# MC1322x register map
Registers from a debugger description file.
Registers are 32-bit, access not given, no defined reset value unless marked. A register's access mark holds for its fields unless they carry their own. Addresses are absolute; registers are grouped by the start of their names; lines under a group give offsets from that group; [hi:lo] are bit positions; {n}, {i} and the like mark numbered series; 'fields as' and 'values as' point back to an identical list; <NAME> marks a mode.

## PAD
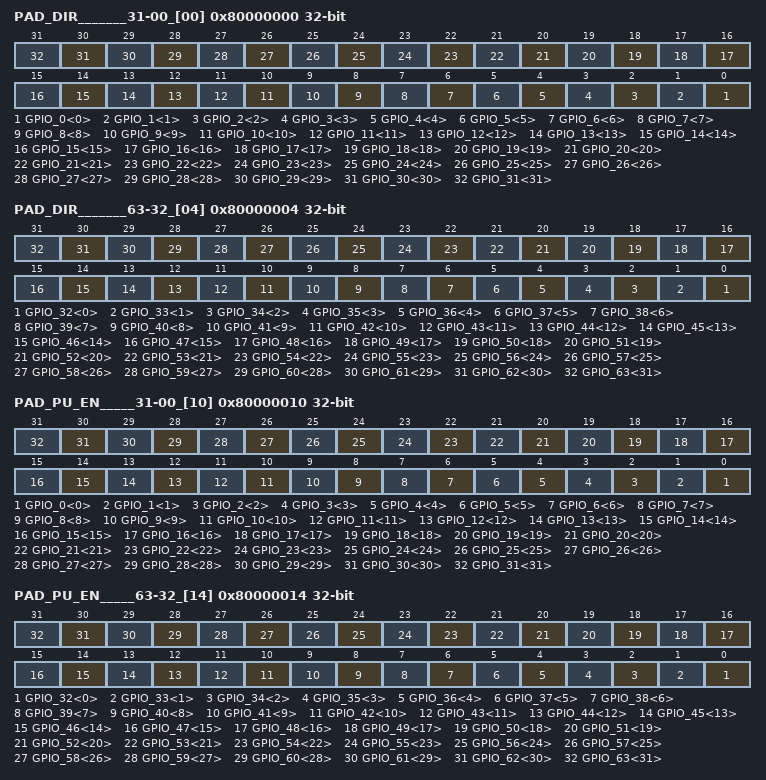
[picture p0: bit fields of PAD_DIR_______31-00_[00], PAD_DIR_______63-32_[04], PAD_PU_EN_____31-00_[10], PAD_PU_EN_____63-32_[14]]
0x80000000 PAD_DIR_______31-00_[00]
  [n] GPIO_{n}<{n}> (n=0..31)
0x80000004 PAD_DIR_______63-32_[04]
  [n-32] GPIO_{n}<{n-32}> (n=32..63)
0x80000010 PAD_PU_EN_____31-00_[10]
  [n] GPIO_{n}<{n}> (n=0..31)
0x80000014 PAD_PU_EN_____63-32_[14]
  [n-32] GPIO_{n}<{n-32}> (n=32..63)
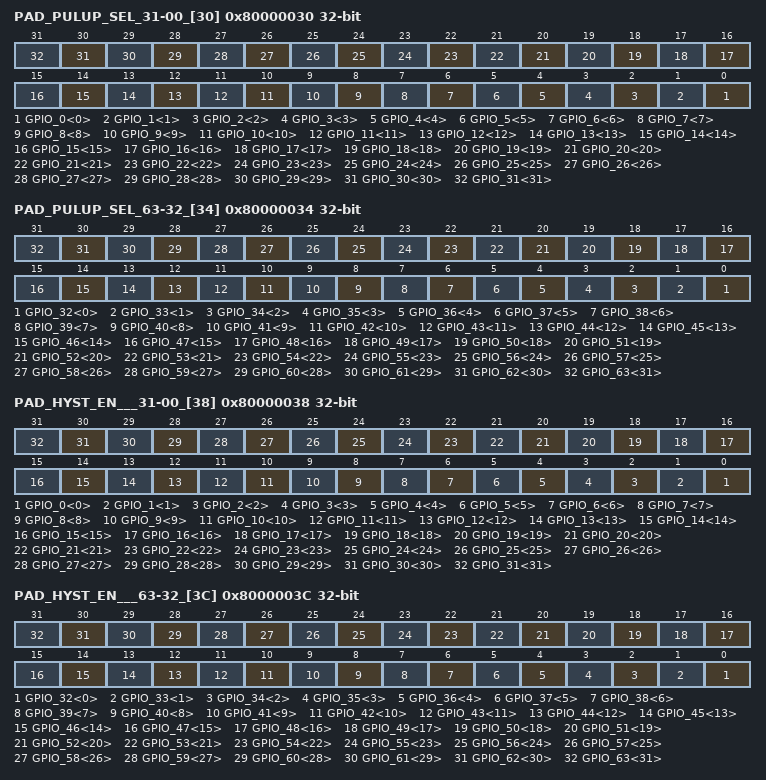
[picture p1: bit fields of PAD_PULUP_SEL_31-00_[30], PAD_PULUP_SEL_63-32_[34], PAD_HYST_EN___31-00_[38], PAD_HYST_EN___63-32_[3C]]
0x80000030 PAD_PULUP_SEL_31-00_[30]
  [n] GPIO_{n}<{n}> (n=0..31)
0x80000034 PAD_PULUP_SEL_63-32_[34]
  [n-32] GPIO_{n}<{n-32}> (n=32..63)
0x80000038 PAD_HYST_EN___31-00_[38]
  [n] GPIO_{n}<{n}> (n=0..31)
0x8000003C PAD_HYST_EN___63-32_[3C]
  [n-32] GPIO_{n}<{n-32}> (n=32..63)

## SFR
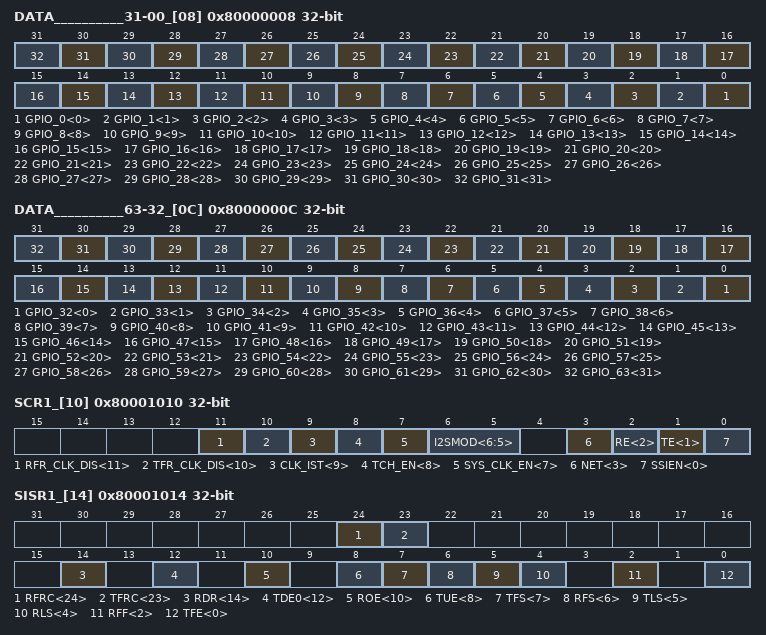
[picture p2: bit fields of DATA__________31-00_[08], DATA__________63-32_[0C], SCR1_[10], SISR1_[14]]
0x80000008 DATA__________31-00_[08]
  [n] GPIO_{n}<{n}> (n=0..31)
0x8000000C DATA__________63-32_[0C]
  [n-32] GPIO_{n}<{n-32}> (n=32..63)
0x80001000 STX_[00]
0x80001008 SRX_[08]
0x80001010 SCR1_[10]
  [11] RFR_CLK_DIS<11>, [10] TFR_CLK_DIS<10>, [9] CLK_IST<9>, [8] TCH_EN<8>, [7] SYS_CLK_EN<7>, [6:5] I2SMOD<6:5>, [3] NET<3>, [2] RE<2>, [1] TE<1>, [0] SSIEN<0>
0x80001014 SISR1_[14]
  [24] RFRC<24>, [23] TFRC<23>, [14] RDR<14>, [12] TDE0<12>, [10] ROE<10>, [8] TUE<8>, [7] TFS<7>, [6] RFS<6>, [5] TLS<5>, [4] RLS<4>, [2] RFF<2>, [0] TFE<0>
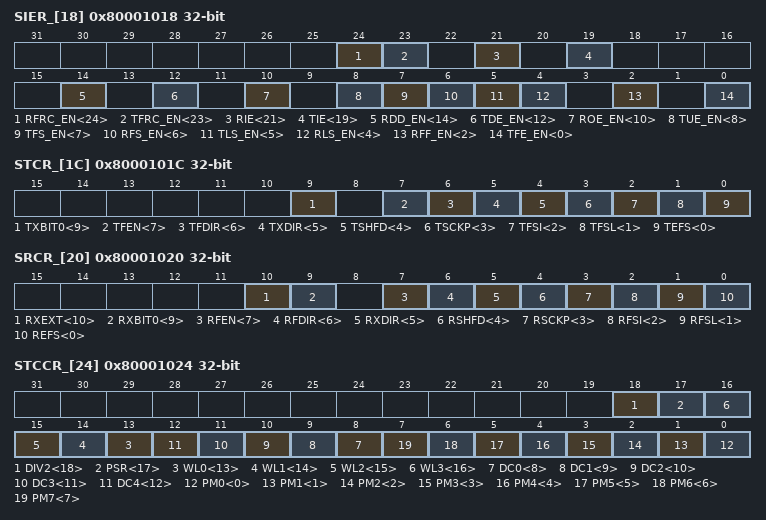
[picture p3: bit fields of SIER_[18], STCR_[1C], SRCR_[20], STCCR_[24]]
0x80001018 SIER_[18]
  [24] RFRC_EN<24>, [23] TFRC_EN<23>, [21] RIE<21>, [19] TIE<19>, [14] RDD_EN<14>, [12] TDE_EN<12>, [10] ROE_EN<10>, [8] TUE_EN<8>, [7] TFS_EN<7>, [6] RFS_EN<6>, [5] TLS_EN<5>, [4] RLS_EN<4>, [2] RFF_EN<2>, [0] TFE_EN<0>
0x8000101C STCR_[1C]
  [9] TXBIT0<9>, [7] TFEN<7>, [6] TFDIR<6>, [5] TXDIR<5>, [4] TSHFD<4>, [3] TSCKP<3>, [2] TFSI<2>, [1] TFSL<1>, [0] TEFS<0>
0x80001020 SRCR_[20]
  [10] RXEXT<10>, [9] RXBIT0<9>, [7] RFEN<7>, [6] RFDIR<6>, [5] RXDIR<5>, [4] RSHFD<4>, [3] RSCKP<3>, [2] RFSI<2>, [1] RFSL<1>, [0] REFS<0>
0x80001024 STCCR_[24]
  [18] DIV2<18>, [17] PSR<17>, [n+13] WL{n}<{n+13}> (n=0..3), [n+8] DC{n}<{n+8}> (n=0..4), [n] PM{n}<{n}> (n=0..7)
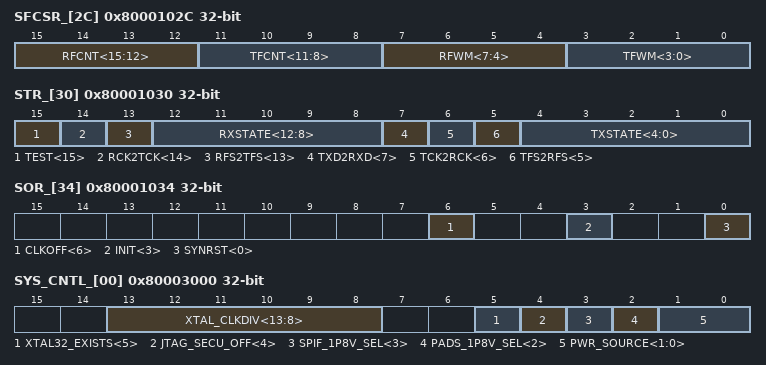
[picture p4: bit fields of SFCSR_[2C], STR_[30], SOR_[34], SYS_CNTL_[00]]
0x8000102C SFCSR_[2C]
  [15:12] RFCNT<15:12>, [11:8] TFCNT<11:8>, [7:4] RFWM<7:4>, [3:0] TFWM<3:0>
0x80001030 STR_[30]
  [15] TEST<15>, [14] RCK2TCK<14>, [13] RFS2TFS<13>, [12:8] RXSTATE<12:8>, [7] TXD2RXD<7>, [6] TCK2RCK<6>, [5] TFS2RFS<5>, [4:0] TXSTATE<4:0>
0x80001034 SOR_[34]
  [6] CLKOFF<6>, [3] INIT<3>, [0] SYNRST<0>
0x80001048 STMSK_[48]
0x8000104C SRMSK_[4C]
0x80003000 SYS_CNTL_[00]
  [13:8] XTAL_CLKDIV<13:8>, [5] XTAL32_EXISTS<5>, [4] JTAG_SECU_OFF<4>, [3] SPIF_1P8V_SEL<3>, [2] PADS_1P8V_SEL<2>, [1:0] PWR_SOURCE<1:0>
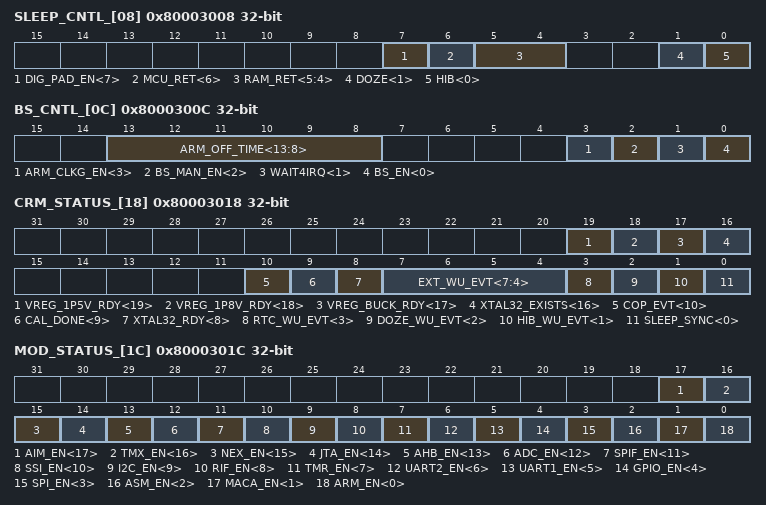
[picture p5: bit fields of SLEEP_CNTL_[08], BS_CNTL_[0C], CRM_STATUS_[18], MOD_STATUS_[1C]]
0x80003008 SLEEP_CNTL_[08]
  [7] DIG_PAD_EN<7>, [6] MCU_RET<6>, [5:4] RAM_RET<5:4>, [1] DOZE<1>, [0] HIB<0>
0x8000300C BS_CNTL_[0C]
  [13:8] ARM_OFF_TIME<13:8>, [3] ARM_CLKG_EN<3>, [2] BS_MAN_EN<2>, [1] WAIT4IRQ<1>, [0] BS_EN<0>
0x80003018 CRM_STATUS_[18]
  [19] VREG_1P5V_RDY<19>, [18] VREG_1P8V_RDY<18>, [17] VREG_BUCK_RDY<17>, [16] XTAL32_EXISTS<16>, [10] COP_EVT<10>, [9] CAL_DONE<9>, [8] XTAL32_RDY<8>, [7:4] EXT_WU_EVT<7:4>, [3] RTC_WU_EVT<3>, [2] DOZE_WU_EVT<2>, [1] HIB_WU_EVT<1>, [0] SLEEP_SYNC<0>
0x8000301C MOD_STATUS_[1C]
  [17] AIM_EN<17>, [16] TMX_EN<16>, [15] NEX_EN<15>, [14] JTA_EN<14>, [13] AHB_EN<13>, [12] ADC_EN<12>, [11] SPIF_EN<11>, [10] SSI_EN<10>, [9] I2C_EN<9>, [8] RIF_EN<8>, [7] TMR_EN<7>, [6] UART2_EN<6>, [5] UART1_EN<5>, [4] GPIO_EN<4>, [3] SPI_EN<3>, [2] ASM_EN<2>, [1] MACA_EN<1>, [0] ARM_EN<0>
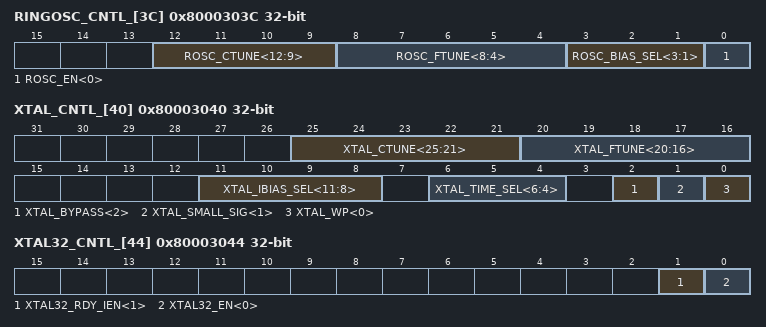
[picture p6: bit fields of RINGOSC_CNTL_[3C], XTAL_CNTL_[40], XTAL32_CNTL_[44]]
0x8000303C RINGOSC_CNTL_[3C]
  [12:9] ROSC_CTUNE<12:9>, [8:4] ROSC_FTUNE<8:4>, [3:1] ROSC_BIAS_SEL<3:1>, [0] ROSC_EN<0>
0x80003040 XTAL_CNTL_[40]
  [25:21] XTAL_CTUNE<25:21>, [20:16] XTAL_FTUNE<20:16>, [11:8] XTAL_IBIAS_SEL<11:8>, [6:4] XTAL_TIME_SEL<6:4>, [2] XTAL_BYPASS<2>, [1] XTAL_SMALL_SIG<1>, [0] XTAL_WP<0>
0x80003044 XTAL32_CNTL_[44]
  [1] XTAL32_RDY_IEN<1>, [0] XTAL32_EN<0>
0x80003050 SW_RST_[50]
